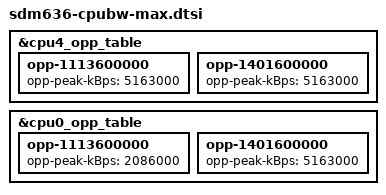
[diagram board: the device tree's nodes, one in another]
// SPDX-License-Identifier: GPL-2.0-only
/*
 * On top of sdm636-cpubw.dtsi. The stock floor alone left
 * memcpy far below the pre-icc-sync_state numbers (2026-10-01: -67..-75 %),
 * and stock had bwmon + memlat on top of it, which are not ported. Here a
 * CPU at its top speed gets full DDR (5163 MB/s = stock's top cpubw level,
 * bimc ~1.3 GHz); light load keeps the stock floor, so idle DDR stays low.
 *   silver 1113.6 / 1401.6 MHz -> 5163 MB/s
 *   gold   1113.6 MHz -> 2086 MB/s, 1401.6 MHz -> 5163 MB/s
 */

&cpu4_opp_table {
	opp-1113600000 { opp-peak-kBps = <5163000>; };
	opp-1401600000 { opp-peak-kBps = <5163000>; };
};

&cpu0_opp_table {
	opp-1113600000 { opp-peak-kBps = <2086000>; };
	opp-1401600000 { opp-peak-kBps = <5163000>; };
};
